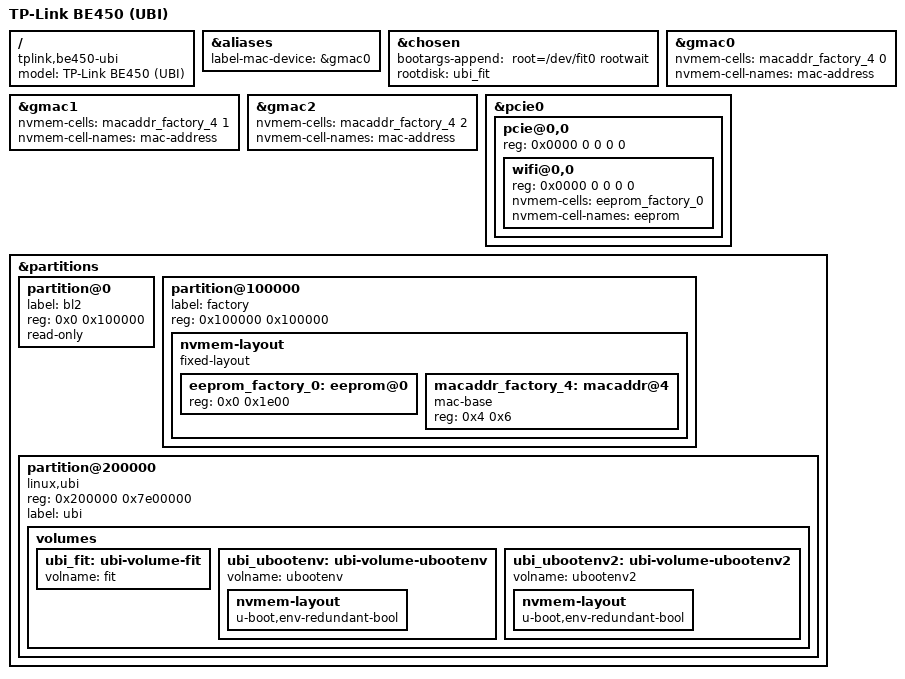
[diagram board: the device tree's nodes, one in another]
// SPDX-License-Identifier: (GPL-2.0 OR MIT)

#include "mt7988d-tplink-be450-common.dtsi"

/ {
	compatible = "tplink,be450-ubi", "mediatek,mt7988d";
	model = "TP-Link BE450 (UBI)";
};

&aliases {
	label-mac-device = &gmac0;
};

&chosen {
	bootargs-append = " root=/dev/fit0 rootwait";
	rootdisk = <&ubi_fit>;
};

&gmac0 {
	nvmem-cells = <&macaddr_factory_4 0>;
	nvmem-cell-names = "mac-address";
};

&gmac1 {
	nvmem-cells = <&macaddr_factory_4 1>;
	nvmem-cell-names = "mac-address";
};

&gmac2 {
	nvmem-cells = <&macaddr_factory_4 2>;
	nvmem-cell-names = "mac-address";
};

&pcie0 {
	pcie@0,0 {
		reg = <0x0000 0 0 0 0>;
		#address-cells = <3>;
		#size-cells = <2>;

		wifi@0,0 {
			reg = <0x0000 0 0 0 0>;
			nvmem-cells = <&eeprom_factory_0>;
			nvmem-cell-names = "eeprom";
		};
	};
};

&partitions {
	partition@0 {
		label = "bl2";
		reg = <0x0 0x100000>;
		read-only;
	};

	partition@100000 {
		label = "factory";
		reg = <0x100000 0x100000>;

		nvmem-layout {
			compatible = "fixed-layout";
			#address-cells = <1>;
			#size-cells = <1>;

			eeprom_factory_0: eeprom@0 {
				reg = <0x0 0x1e00>;
			};

			macaddr_factory_4: macaddr@4 {
				compatible = "mac-base";
				reg = <0x4 0x6>;
				#nvmem-cell-cells = <1>;
			};
		};
	};

	partition@200000 {
		compatible = "linux,ubi";
		reg = <0x200000 0x7e00000>;
		label = "ubi";

		volumes {
			ubi_fit: ubi-volume-fit {
				volname = "fit";
			};

			ubi_ubootenv: ubi-volume-ubootenv {
				volname = "ubootenv";
			};

			ubi_ubootenv2: ubi-volume-ubootenv2 {
				volname = "ubootenv2";
			};
		};
	};
};

&ubi_ubootenv {
	nvmem-layout {
		compatible = "u-boot,env-redundant-bool";
	};
};

&ubi_ubootenv2 {
	nvmem-layout {
		compatible = "u-boot,env-redundant-bool";
	};
};
